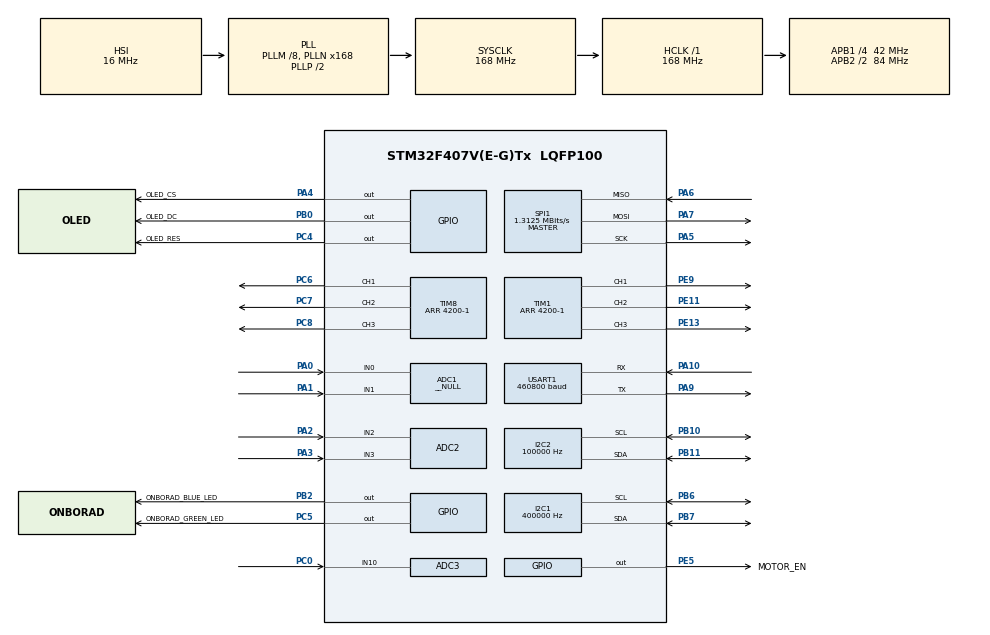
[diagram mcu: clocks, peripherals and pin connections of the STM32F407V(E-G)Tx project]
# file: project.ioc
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ADC1.Channel-1\#ChannelRegularConversion=ADC_CHANNEL_0
ADC1.Channel-2\#ChannelInjectedConversion=ADC_CHANNEL_0
ADC1.Channel-3\#ChannelInjectedConversion=ADC_CHANNEL_1
ADC1.ExternalTrigInjecConv=ADC_EXTERNALTRIGINJECCONV_T1_TRGO
ADC1.InjNumberOfConversion=2
ADC1.InjectedOffset-2\#ChannelInjectedConversion=0
ADC1.InjectedOffset-3\#ChannelInjectedConversion=0
ADC1.InjectedRank-2\#ChannelInjectedConversion=1
ADC1.InjectedRank-3\#ChannelInjectedConversion=2
ADC1.Mode=__NULL
ADC1.NbrOfConversion=1
ADC1.NbrOfConversionFlag=1
ADC1.Rank-1\#ChannelRegularConversion=1
ADC1.SamplingTime-1\#ChannelRegularConversion=ADC_SAMPLETIME_3CYCLES
ADC1.SamplingTime-2\#ChannelInjectedConversion=ADC_SAMPLETIME_15CYCLES
ADC1.SamplingTime-3\#ChannelInjectedConversion=ADC_SAMPLETIME_15CYCLES
ADC1.master=1
ADC2.Channel-4\#ChannelRegularConversion=ADC_CHANNEL_2
ADC2.Channel-5\#ChannelInjectedConversion=ADC_CHANNEL_2
ADC2.Channel-6\#ChannelInjectedConversion=ADC_CHANNEL_3
ADC2.ExternalTrigInjecConv=ADC_EXTERNALTRIGINJECCONV_T8_CC4
ADC2.InjNumberOfConversion=2
ADC2.InjectedOffset-5\#ChannelInjectedConversion=0
ADC2.InjectedOffset-6\#ChannelInjectedConversion=0
ADC2.InjectedRank-5\#ChannelInjectedConversion=1
ADC2.InjectedRank-6\#ChannelInjectedConversion=2
ADC2.NbrOfConversion=1
ADC2.NbrOfConversionFlag=1
ADC2.Rank-4\#ChannelRegularConversion=1
ADC2.SamplingTime-4\#ChannelRegularConversion=ADC_SAMPLETIME_3CYCLES
ADC2.SamplingTime-5\#ChannelInjectedConversion=ADC_SAMPLETIME_15CYCLES
ADC2.SamplingTime-6\#ChannelInjectedConversion=ADC_SAMPLETIME_15CYCLES
ADC3.Channel-1\#ChannelRegularConversion=ADC_CHANNEL_10
ADC3.ContinuousConvMode=ENABLE
ADC3.DMAContinuousRequests=ENABLE
ADC3.NbrOfConversion=1
ADC3.NbrOfConversionFlag=1
ADC3.Rank-1\#ChannelRegularConversion=1
ADC3.SamplingTime-1\#ChannelRegularConversion=ADC_SAMPLETIME_84CYCLES
Dma.ADC3.5.Direction=DMA_PERIPH_TO_MEMORY
Dma.ADC3.5.FIFOMode=DMA_FIFOMODE_DISABLE
Dma.ADC3.5.Instance=DMA2_Stream1
Dma.ADC3.5.MemDataAlignment=DMA_MDATAALIGN_HALFWORD
Dma.ADC3.5.MemInc=DMA_MINC_ENABLE
Dma.ADC3.5.Mode=DMA_CIRCULAR
Dma.ADC3.5.PeriphDataAlignment=DMA_PDATAALIGN_HALFWORD
Dma.ADC3.5.PeriphInc=DMA_PINC_DISABLE
Dma.ADC3.5.Priority=DMA_PRIORITY_LOW
Dma.I2C1_RX.0.Direction=DMA_PERIPH_TO_MEMORY
Dma.I2C1_RX.0.FIFOMode=DMA_FIFOMODE_DISABLE
Dma.I2C1_RX.0.Instance=DMA1_Stream0
Dma.I2C1_RX.0.MemDataAlignment=DMA_MDATAALIGN_BYTE
Dma.I2C1_RX.0.MemInc=DMA_MINC_ENABLE
Dma.I2C1_RX.0.Mode=DMA_NORMAL
Dma.I2C1_RX.0.PeriphDataAlignment=DMA_PDATAALIGN_BYTE
Dma.I2C1_RX.0.PeriphInc=DMA_PINC_DISABLE
Dma.I2C1_RX.0.Priority=DMA_PRIORITY_LOW
Dma.I2C1_TX.6.Direction=DMA_MEMORY_TO_PERIPH
Dma.I2C1_TX.6.FIFOMode=DMA_FIFOMODE_DISABLE
Dma.I2C1_TX.6.Instance=DMA1_Stream6
Dma.I2C1_TX.6.MemDataAlignment=DMA_MDATAALIGN_BYTE
Dma.I2C1_TX.6.MemInc=DMA_MINC_ENABLE
Dma.I2C1_TX.6.Mode=DMA_NORMAL
Dma.I2C1_TX.6.PeriphDataAlignment=DMA_PDATAALIGN_BYTE
Dma.I2C1_TX.6.PeriphInc=DMA_PINC_DISABLE
Dma.I2C1_TX.6.Priority=DMA_PRIORITY_LOW
Dma.I2C2_RX.1.Direction=DMA_PERIPH_TO_MEMORY
Dma.I2C2_RX.1.FIFOMode=DMA_FIFOMODE_DISABLE
Dma.I2C2_RX.1.Instance=DMA1_Stream2
Dma.I2C2_RX.1.MemDataAlignment=DMA_MDATAALIGN_BYTE
Dma.I2C2_RX.1.MemInc=DMA_MINC_ENABLE
Dma.I2C2_RX.1.Mode=DMA_NORMAL
Dma.I2C2_RX.1.PeriphDataAlignment=DMA_PDATAALIGN_BYTE
Dma.I2C2_RX.1.PeriphInc=DMA_PINC_DISABLE
Dma.I2C2_RX.1.Priority=DMA_PRIORITY_LOW
Dma.I2C2_TX.7.Direction=DMA_MEMORY_TO_PERIPH
Dma.I2C2_TX.7.FIFOMode=DMA_FIFOMODE_DISABLE
Dma.I2C2_TX.7.Instance=DMA1_Stream7
Dma.I2C2_TX.7.MemDataAlignment=DMA_MDATAALIGN_BYTE
Dma.I2C2_TX.7.MemInc=DMA_MINC_ENABLE
Dma.I2C2_TX.7.Mode=DMA_NORMAL
Dma.I2C2_TX.7.PeriphDataAlignment=DMA_PDATAALIGN_BYTE
Dma.I2C2_TX.7.PeriphInc=DMA_PINC_DISABLE
Dma.I2C2_TX.7.Priority=DMA_PRIORITY_LOW
Dma.Request0=I2C1_RX
Dma.Request1=I2C2_RX
Dma.Request2=USART1_TX
Dma.Request3=SPI1_RX
Dma.Request4=SPI1_TX
Dma.Request5=ADC3
Dma.Request6=I2C1_TX
Dma.Request7=I2C2_TX
Dma.Request8=USART1_RX
Dma.SPI1_RX.3.Direction=DMA_PERIPH_TO_MEMORY
Dma.SPI1_RX.3.FIFOMode=DMA_FIFOMODE_DISABLE
Dma.SPI1_RX.3.Instance=DMA2_Stream0
Dma.SPI1_RX.3.MemDataAlignment=DMA_MDATAALIGN_BYTE
Dma.SPI1_RX.3.MemInc=DMA_MINC_ENABLE
Dma.SPI1_RX.3.Mode=DMA_NORMAL
Dma.SPI1_RX.3.PeriphDataAlignment=DMA_PDATAALIGN_BYTE
Dma.SPI1_RX.3.PeriphInc=DMA_PINC_DISABLE
Dma.SPI1_RX.3.Priority=DMA_PRIORITY_LOW
Dma.SPI1_TX.4.Direction=DMA_MEMORY_TO_PERIPH
Dma.SPI1_TX.4.FIFOMode=DMA_FIFOMODE_DISABLE
Dma.SPI1_TX.4.Instance=DMA2_Stream3
Dma.SPI1_TX.4.MemDataAlignment=DMA_MDATAALIGN_BYTE
Dma.SPI1_TX.4.MemInc=DMA_MINC_ENABLE
Dma.SPI1_TX.4.Mode=DMA_NORMAL
Dma.SPI1_TX.4.PeriphDataAlignment=DMA_PDATAALIGN_BYTE
Dma.SPI1_TX.4.PeriphInc=DMA_PINC_DISABLE
Dma.SPI1_TX.4.Priority=DMA_PRIORITY_LOW
Dma.USART1_RX.8.Direction=DMA_PERIPH_TO_MEMORY
Dma.USART1_RX.8.FIFOMode=DMA_FIFOMODE_DISABLE
Dma.USART1_RX.8.Instance=DMA2_Stream2
Dma.USART1_RX.8.MemDataAlignment=DMA_MDATAALIGN_BYTE
Dma.USART1_RX.8.MemInc=DMA_MINC_ENABLE
Dma.USART1_RX.8.Mode=DMA_CIRCULAR
Dma.USART1_RX.8.PeriphDataAlignment=DMA_PDATAALIGN_BYTE
Dma.USART1_RX.8.PeriphInc=DMA_PINC_DISABLE
Dma.USART1_RX.8.Priority=DMA_PRIORITY_LOW
Dma.USART1_TX.2.Direction=DMA_MEMORY_TO_PERIPH
Dma.USART1_TX.2.FIFOMode=DMA_FIFOMODE_DISABLE
Dma.USART1_TX.2.Instance=DMA2_Stream7
Dma.USART1_TX.2.MemDataAlignment=DMA_MDATAALIGN_BYTE
Dma.USART1_TX.2.MemInc=DMA_MINC_ENABLE
Dma.USART1_TX.2.Mode=DMA_NORMAL
Dma.USART1_TX.2.PeriphDataAlignment=DMA_PDATAALIGN_BYTE
Dma.USART1_TX.2.PeriphInc=DMA_PINC_DISABLE
Dma.USART1_TX.2.Priority=DMA_PRIORITY_LOW
FREERTOS.Tasks01=defaultTask,24,128,StartDefaultTask,Default,NULL,Dynamic,NULL,NULL
FREERTOS.configENABLE_FPU=1
I2C1.ClockSpeed=400000
I2C1.I2C_Mode=I2C_Standard
I2C2.ClockSpeed=100000
I2C2.I2C_Mode=I2C_Standard
Mcu.Family=STM32F4
Mcu.Name=STM32F407V(E-G)Tx
Mcu.Package=LQFP100
NVIC.DMA1_Stream0_IRQn=true\:5\:0\:false\:false\:true\:true\:false\:true\:true
NVIC.DMA1_Stream2_IRQn=true\:5\:0\:false\:false\:true\:true\:false\:true\:true
NVIC.DMA1_Stream6_IRQn=true\:5\:0\:false\:false\:true\:true\:false\:true\:true
NVIC.DMA1_Stream7_IRQn=true\:5\:0\:false\:false\:true\:true\:false\:true\:true
NVIC.DMA2_Stream0_IRQn=true\:5\:0\:false\:false\:true\:true\:false\:true\:true
NVIC.DMA2_Stream1_IRQn=true\:5\:0\:false\:false\:true\:true\:false\:true\:true
NVIC.DMA2_Stream2_IRQn=true\:5\:0\:false\:false\:true\:true\:false\:true\:true
NVIC.DMA2_Stream3_IRQn=true\:5\:0\:false\:false\:true\:true\:false\:true\:true
NVIC.DMA2_Stream7_IRQn=true\:5\:0\:false\:false\:true\:true\:false\:true\:true
NVIC.I2C1_ER_IRQn=true\:5\:0\:false\:false\:true\:true\:true\:true\:true
NVIC.I2C1_EV_IRQn=true\:5\:0\:false\:false\:true\:true\:true\:true\:true
NVIC.I2C2_ER_IRQn=true\:5\:0\:false\:false\:true\:true\:true\:true\:true
NVIC.I2C2_EV_IRQn=true\:5\:0\:false\:false\:true\:true\:true\:true\:true
NVIC.PriorityGroup=NVIC_PRIORITYGROUP_4
NVIC.SPI1_IRQn=true\:5\:0\:false\:false\:true\:true\:true\:true\:true
NVIC.TIM1_UP_TIM10_IRQn=true\:5\:0\:false\:false\:true\:true\:true\:true\:true
NVIC.TIM8_TRG_COM_TIM14_IRQn=true\:15\:0\:false\:false\:true\:false\:false\:true\:true
NVIC.TIM8_UP_TIM13_IRQn=true\:5\:0\:false\:false\:true\:true\:true\:true\:true
NVIC.TimeBase=TIM8_TRG_COM_TIM14_IRQn
NVIC.TimeBaseIP=TIM14
NVIC.USART1_IRQn=true\:5\:0\:false\:false\:true\:true\:true\:true\:true
PA0-WKUP.Signal=ADCx_IN0
PA1.Signal=ADCx_IN1
PA10.Mode=Asynchronous
PA10.Signal=USART1_RX
PA13.Mode=Serial_Wire
PA13.Signal=SYS_JTMS-SWDIO
PA14.Mode=Serial_Wire
PA14.Signal=SYS_JTCK-SWCLK
PA2.Signal=ADCx_IN2
PA3.Signal=ADCx_IN3
PA4.GPIO_Label=OLED_CS
PA4.PinState=GPIO_PIN_SET
PA4.Signal=GPIO_Output
PA5.Mode=Full_Duplex_Master
PA5.Signal=SPI1_SCK
PA6.Mode=Full_Duplex_Master
PA6.Signal=SPI1_MISO
PA7.Mode=Full_Duplex_Master
PA7.Signal=SPI1_MOSI
PA9.Mode=Asynchronous
PA9.Signal=USART1_TX
PB0.GPIO_Label=OLED_DC
PB0.PinState=GPIO_PIN_SET
PB0.Signal=GPIO_Output
PB10.Mode=I2C
PB10.Signal=I2C2_SCL
PB11.Mode=I2C
PB11.Signal=I2C2_SDA
PB2.GPIO_Label=ONBORAD_BLUE_LED
PB2.PinState=GPIO_PIN_SET
PB2.Signal=GPIO_Output
PB6.Mode=I2C
PB6.Signal=I2C1_SCL
PB7.Mode=I2C
PB7.Signal=I2C1_SDA
PC0.Signal=ADCx_IN10
PC4.GPIO_Label=OLED_RES
PC4.PinState=GPIO_PIN_SET
PC4.Signal=GPIO_Output
PC5.GPIO_Label=ONBORAD_GREEN_LED
PC5.PinState=GPIO_PIN_SET
PC5.Signal=GPIO_Output
PC6.Signal=S_TIM8_CH1
PC7.Signal=S_TIM8_CH2
PC8.Signal=S_TIM8_CH3
PE11.Signal=S_TIM1_CH2
PE13.Signal=S_TIM1_CH3
PE5.GPIO_Label=MOTOR_EN
PE5.PinState=GPIO_PIN_RESET
PE5.Signal=GPIO_Output
PE9.Signal=S_TIM1_CH1
PH0-OSC_IN.Mode=HSE-External-Oscillator
PH0-OSC_IN.Signal=RCC_OSC_IN
PH1-OSC_OUT.Mode=HSE-External-Oscillator
PH1-OSC_OUT.Signal=RCC_OSC_OUT
ProjectManager.HeapSize=0x200
ProjectManager.StackSize=0x400
ProjectManager.TargetToolchain=CMake
RCC.48MHZClocksFreq_Value=84000000
RCC.AHBFreq_Value=168000000
RCC.APB1CLKDivider=RCC_HCLK_DIV4
RCC.APB1Freq_Value=42000000
RCC.APB1TimFreq_Value=84000000
RCC.APB2CLKDivider=RCC_HCLK_DIV2
RCC.APB2Freq_Value=84000000
RCC.APB2TimFreq_Value=168000000
RCC.CortexFreq_Value=168000000
RCC.HCLKFreq_Value=168000000
RCC.HSE_VALUE=25000000
RCC.HSI_VALUE=16000000
RCC.LSE_VALUE=32768
RCC.PLLM=8
RCC.PLLN=168
RCC.SYSCLKFreq_VALUE=168000000
RCC.SYSCLKSource=RCC_SYSCLKSOURCE_PLLCLK
RCC.VCOOutputFreq_Value=336000000
SH.ADCx_IN0.0=ADC1_IN0,IN0
SH.ADCx_IN1.0=ADC1_IN1,IN1
SH.ADCx_IN10.0=ADC3_IN10,IN10
SH.ADCx_IN2.0=ADC2_IN2,IN2
SH.ADCx_IN3.0=ADC2_IN3,IN3
SH.S_TIM1_CH1.0=TIM1_CH1,PWM Generation1 CH1
SH.S_TIM1_CH2.0=TIM1_CH2,PWM Generation2 CH2
SH.S_TIM1_CH3.0=TIM1_CH3,PWM Generation3 CH3
SH.S_TIM8_CH1.0=TIM8_CH1,PWM Generation1 CH1
SH.S_TIM8_CH2.0=TIM8_CH2,PWM Generation2 CH2
SH.S_TIM8_CH3.0=TIM8_CH3,PWM Generation3 CH3
SPI1.BaudRatePrescaler=SPI_BAUDRATEPRESCALER_64
SPI1.CalculateBaudRate=1.3125 MBits/s
SPI1.Direction=SPI_DIRECTION_2LINES
SPI1.Mode=SPI_MODE_MASTER
SPI1.VirtualType=VM_MASTER
TIM1.AutoReloadPreload=TIM_AUTORELOAD_PRELOAD_ENABLE
TIM1.Channel-PWM\ Generation1\ CH1=TIM_CHANNEL_1
TIM1.Channel-PWM\ Generation2\ CH2=TIM_CHANNEL_2
TIM1.Channel-PWM\ Generation3\ CH3=TIM_CHANNEL_3
TIM1.Channel-PWM\ Generation4\ No\ Output=TIM_CHANNEL_4
TIM1.CounterMode=TIM_COUNTERMODE_CENTERALIGNED1
TIM1.Period=4200-1
TIM1.Pulse-PWM\ Generation1\ CH1=2100
TIM1.Pulse-PWM\ Generation2\ CH2=2100
TIM1.Pulse-PWM\ Generation3\ CH3=2100
TIM1.Pulse-PWM\ Generation4\ No\ Output=4198
TIM1.RepetitionCounter=3
TIM1.TIM_MasterOutputTrigger=TIM_TRGO_OC4REF
TIM1.TIM_MasterSlaveMode=TIM_MASTERSLAVEMODE_ENABLE
TIM5.Prescaler=83
TIM8.AutoReloadPreload=TIM_AUTORELOAD_PRELOAD_ENABLE
TIM8.Channel-PWM\ Generation1\ CH1=TIM_CHANNEL_1
TIM8.Channel-PWM\ Generation2\ CH2=TIM_CHANNEL_2
TIM8.Channel-PWM\ Generation3\ CH3=TIM_CHANNEL_3
TIM8.Channel-PWM\ Generation4\ No\ Output=TIM_CHANNEL_4
TIM8.CounterMode=TIM_COUNTERMODE_CENTERALIGNED1
TIM8.Period=4200-1
TIM8.Pulse-PWM\ Generation1\ CH1=2100
TIM8.Pulse-PWM\ Generation2\ CH2=2100
TIM8.Pulse-PWM\ Generation3\ CH3=2100
TIM8.Pulse-PWM\ Generation4\ No\ Output=4198
TIM8.RepetitionCounter=3
TIM8.TIM_MasterOutputTrigger=TIM_TRGO_OC4REF
TIM8.TIM_MasterSlaveMode=TIM_MASTERSLAVEMODE_ENABLE
USART1.BaudRate=460800
USART1.VirtualMode=VM_ASYNC
VP_FREERTOS_VS_CMSIS_V2.Mode=CMSIS_V2
VP_SYS_VS_tim14.Mode=TIM14
VP_TIM1_VS_ClockSourceINT.Mode=Internal
VP_TIM1_VS_no_output4.Mode=PWM Generation4 No Output
VP_TIM5_VS_ClockSourceINT.Mode=Internal
VP_TIM8_VS_ClockSourceINT.Mode=Internal
VP_TIM8_VS_no_output4.Mode=PWM Generation4 No Output
board=custom

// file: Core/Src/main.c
/* USER CODE BEGIN Header */
/**
  ******************************************************************************
  * @file           : main.c
  * @brief          : Main program body
  ******************************************************************************
  * @attention
  *
  * Copyright (c) 2026 STMicroelectronics.
  * All rights reserved.
  *
  * This software is licensed under terms that can be found in the LICENSE file
  * in the root directory of this software component.
  * If no LICENSE file comes with this software, it is provided AS-IS.
  *
  ******************************************************************************
  */
/* USER CODE END Header */
#include "main.h"
#include "cmsis_os.h"
#include "adc.h"
#include "dma.h"
#include "i2c.h"
#include "spi.h"
#include "tim.h"
#include "usart.h"
#include "gpio.h"

void SystemClock_Config(void);
void MX_FREERTOS_Init(void);

int main(void)
{

  /* MCU Configuration--------------------------------------------------------*/

  /* Reset of all peripherals, Initializes the Flash interface and the Systick. */
  HAL_Init();

  /* Configure the system clock */
  SystemClock_Config();

  /* Initialize all configured peripherals */
  MX_GPIO_Init();
  MX_DMA_Init();
  MX_I2C1_Init();
  MX_TIM1_Init();
  MX_I2C2_Init();
  MX_ADC1_Init();
  MX_ADC2_Init();
  MX_ADC3_Init();
  MX_SPI1_Init();
  MX_TIM8_Init();
  MX_USART1_UART_Init();
  MX_TIM5_Init();

  /* Init scheduler */
  osKernelInitialize();  /* Call init function for freertos objects (in cmsis_os2.c) */
  MX_FREERTOS_Init();

  /* Start scheduler */
  osKernelStart();

  /* We should never get here as control is now taken by the scheduler */

  /* Infinite loop */
  while (1)
  {

  }
}

void SystemClock_Config(void)
{
  RCC_OscInitTypeDef RCC_OscInitStruct = {0};
  RCC_ClkInitTypeDef RCC_ClkInitStruct = {0};

  /** Configure the main internal regulator output voltage
  */
  __HAL_RCC_PWR_CLK_ENABLE();
  __HAL_PWR_VOLTAGESCALING_CONFIG(PWR_REGULATOR_VOLTAGE_SCALE1);

  /** Initializes the RCC Oscillators according to the specified parameters
  * in the RCC_OscInitTypeDef structure.
  */
  RCC_OscInitStruct.OscillatorType = RCC_OSCILLATORTYPE_HSI;
  RCC_OscInitStruct.HSIState = RCC_HSI_ON;
  RCC_OscInitStruct.HSICalibrationValue = RCC_HSICALIBRATION_DEFAULT;
  RCC_OscInitStruct.PLL.PLLState = RCC_PLL_ON;
  RCC_OscInitStruct.PLL.PLLSource = RCC_PLLSOURCE_HSI;
  RCC_OscInitStruct.PLL.PLLM = 8;
  RCC_OscInitStruct.PLL.PLLN = 168;
  RCC_OscInitStruct.PLL.PLLP = RCC_PLLP_DIV2;
  RCC_OscInitStruct.PLL.PLLQ = 4;
  if (HAL_RCC_OscConfig(&RCC_OscInitStruct) != HAL_OK)
  {
    Error_Handler();
  }

  /** Initializes the CPU, AHB and APB buses clocks
  */
  RCC_ClkInitStruct.ClockType = RCC_CLOCKTYPE_HCLK|RCC_CLOCKTYPE_SYSCLK
                              |RCC_CLOCKTYPE_PCLK1|RCC_CLOCKTYPE_PCLK2;
  RCC_ClkInitStruct.SYSCLKSource = RCC_SYSCLKSOURCE_PLLCLK;
  RCC_ClkInitStruct.AHBCLKDivider = RCC_SYSCLK_DIV1;
  RCC_ClkInitStruct.APB1CLKDivider = RCC_HCLK_DIV4;
  RCC_ClkInitStruct.APB2CLKDivider = RCC_HCLK_DIV2;

  if (HAL_RCC_ClockConfig(&RCC_ClkInitStruct, FLASH_LATENCY_5) != HAL_OK)
  {
    Error_Handler();
  }
}

void HAL_TIM_PeriodElapsedCallback(TIM_HandleTypeDef *htim)
{
  if (htim->Instance == TIM14)
  {
    HAL_IncTick();
  }
}

void Error_Handler(void)
{
  __disable_irq();
  while (1)
  {
  }
}

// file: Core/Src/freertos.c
/* USER CODE BEGIN Header */
/**
  ******************************************************************************
  * File Name          : freertos.c
  * Description        : Code for freertos applications
  ******************************************************************************
  * @attention
  *
  * Copyright (c) 2026 STMicroelectronics.
  * All rights reserved.
  *
  * This software is licensed under terms that can be found in the LICENSE file
  * in the root directory of this software component.
  * If no LICENSE file comes with this software, it is provided AS-IS.
  *
  ******************************************************************************
  */
/* USER CODE END Header */

#include "FreeRTOS.h"
#include "task.h"
#include "main.h"
#include "cmsis_os.h"

/* Definitions for defaultTask */
osThreadId_t defaultTaskHandle;
const osThreadAttr_t defaultTask_attributes = {
  .name = "defaultTask",
  .stack_size = 128 * 4,
  .priority = (osPriority_t) osPriorityNormal,
};

/* USER CODE BEGIN FunctionPrototypes */
extern void start_init_all(void);

/* USER CODE END FunctionPrototypes */

void StartDefaultTask(void *argument);

void MX_FREERTOS_Init(void); /* (MISRA C 2004 rule 8.1) */

void MX_FREERTOS_Init(void) {
  /* USER CODE BEGIN Init */
  start_init_all();

  /* USER CODE END Init */

  /* Create the thread(s) */
  /* creation of defaultTask */
  defaultTaskHandle = osThreadNew(StartDefaultTask, NULL, &defaultTask_attributes);

}

void StartDefaultTask(void *argument)
{
  for(;;)
  {
    osDelay(1);
  }
}
